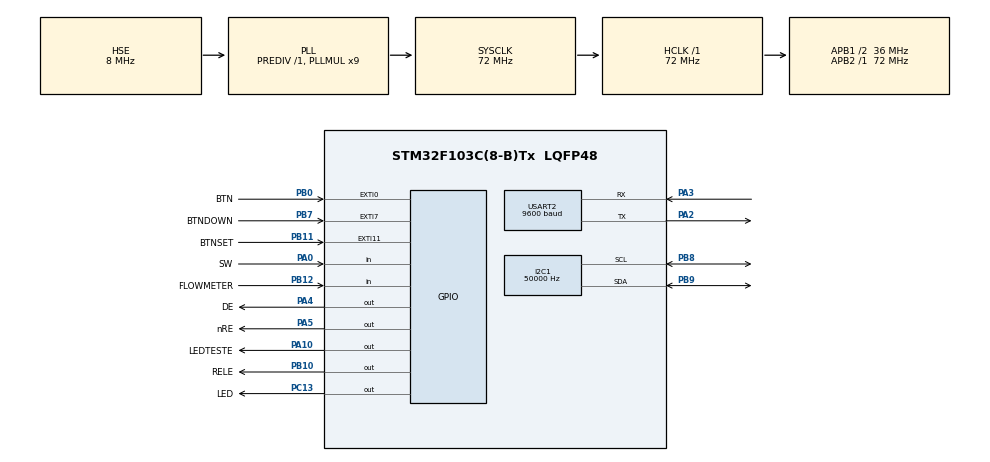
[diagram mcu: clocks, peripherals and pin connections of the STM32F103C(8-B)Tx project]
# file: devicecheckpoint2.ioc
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I2C1.ClockSpeed=50000
Mcu.Family=STM32F1
Mcu.Name=STM32F103C(8-B)Tx
Mcu.Package=LQFP48
NVIC.EXTI0_IRQn=true\:4\:0\:true\:false\:true\:true\:true
NVIC.EXTI15_10_IRQn=true\:3\:0\:true\:false\:true\:true\:true
NVIC.EXTI9_5_IRQn=true\:4\:0\:true\:false\:true\:true\:true
NVIC.PriorityGroup=NVIC_PRIORITYGROUP_4
NVIC.TIM2_IRQn=true\:2\:0\:true\:false\:true\:true\:true
NVIC.USART2_IRQn=true\:1\:0\:true\:false\:true\:true\:true
PA0-WKUP.GPIO_Label=SW
PA0-WKUP.GPIO_PuPd=GPIO_PULLUP
PA0-WKUP.Signal=GPIO_Input
PA10.GPIO_Label=LEDTESTE
PA10.Signal=GPIO_Output
PA13.Mode=Serial_Wire
PA13.Signal=SYS_JTMS-SWDIO
PA14.Mode=Serial_Wire
PA14.Signal=SYS_JTCK-SWCLK
PA2.Mode=Asynchronous
PA2.Signal=USART2_TX
PA3.Mode=Asynchronous
PA3.Signal=USART2_RX
PA4.GPIO_Label=DE
PA4.Signal=GPIO_Output
PA5.GPIO_Label=nRE
PA5.Signal=GPIO_Output
PB0.GPIO_Label=BTN
PB0.GPIO_ModeDefaultEXTI=GPIO_MODE_IT_FALLING
PB0.GPIO_PuPd=GPIO_NOPULL
PB0.Signal=GPXTI0
PB10.GPIO_Label=RELE
PB10.Signal=GPIO_Output
PB11.GPIO_Label=BTNSET
PB11.GPIO_ModeDefaultEXTI=GPIO_MODE_IT_FALLING
PB11.Signal=GPXTI11
PB12.GPIO_Label=FLOWMETER
PB12.Signal=GPIO_Input
PB7.GPIO_Label=BTNDOWN
PB7.GPIO_ModeDefaultEXTI=GPIO_MODE_IT_FALLING
PB7.Signal=GPXTI7
PB8.Mode=I2C
PB8.Signal=I2C1_SCL
PB9.Mode=I2C
PB9.Signal=I2C1_SDA
PC13-TAMPER-RTC.GPIO_Label=LED
PC13-TAMPER-RTC.Signal=GPIO_Output
PC14-OSC32_IN.Mode=LSE-External-Oscillator
PC14-OSC32_IN.Signal=RCC_OSC32_IN
PC15-OSC32_OUT.Mode=LSE-External-Oscillator
PC15-OSC32_OUT.Signal=RCC_OSC32_OUT
PD0-OSC_IN.Mode=HSE-External-Oscillator
PD0-OSC_IN.Signal=RCC_OSC_IN
PD1-OSC_OUT.Mode=HSE-External-Oscillator
PD1-OSC_OUT.Signal=RCC_OSC_OUT
ProjectManager.HeapSize=0x200
ProjectManager.StackSize=0x400
ProjectManager.TargetToolchain=TrueSTUDIO
RCC.AHBFreq_Value=72000000
RCC.APB1CLKDivider=RCC_HCLK_DIV2
RCC.APB1Freq_Value=36000000
RCC.APB1TimFreq_Value=72000000
RCC.APB2Freq_Value=72000000
RCC.APB2TimFreq_Value=72000000
RCC.HCLKFreq_Value=72000000
RCC.PLLMUL=RCC_PLL_MUL9
RCC.PLLSourceVirtual=RCC_PLLSOURCE_HSE
RCC.SYSCLKFreq_VALUE=72000000
RCC.SYSCLKSource=RCC_SYSCLKSOURCE_PLLCLK
RCC.USBFreq_Value=72000000
TIM2.Period=999
TIM2.Prescaler=71
USART2.BaudRate=9600
USART2.VirtualMode=VM_ASYNC
VP_TIM2_VS_ClockSourceINT.Mode=Internal
board=custom

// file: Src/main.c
/* USER CODE BEGIN Header */
/**
  ******************************************************************************
  * @file           : main.c
  * @brief          : Main program body
  ******************************************************************************
  * @attention
  *
  * <h2><center>&copy; Copyright (c) 2019 STMicroelectronics.
  * All rights reserved.</center></h2>
  *
  * This software component is licensed by ST under BSD 3-Clause license,
  * the "License"; You may not use this file except in compliance with the
  * License. You may obtain a copy of the License at:
  *                        opensource.org/licenses/BSD-3-Clause
  *
  ******************************************************************************
  */
/* USER CODE END Header */

#include "main.h"

/* USER CODE BEGIN Includes */
#include <stdbool.h>
#include "app.h"
#include "i2c-lcd.h"
/* USER CODE END Includes */

/* USER CODE BEGIN PTD */
static uint32_t tick_ms = 0;
/* USER CODE END PTD */

I2C_HandleTypeDef hi2c1;

TIM_HandleTypeDef htim2;

UART_HandleTypeDef huart2;

void SystemClock_Config(void);
static void MX_GPIO_Init(void);
static void MX_USART2_UART_Init(void);
static void MX_TIM2_Init(void);
static void MX_I2C1_Init(void);

int main(void)
{

  /* MCU Configuration--------------------------------------------------------*/

  /* Reset of all peripherals, Initializes the Flash interface and the Systick. */
  HAL_Init();

  /* Configure the system clock */
  SystemClock_Config();

  /* Initialize all configured peripherals */
  MX_GPIO_Init();
  MX_USART2_UART_Init();
  MX_TIM2_Init();
  MX_I2C1_Init();
  /* USER CODE BEGIN 2 */
  HAL_TIM_Base_Start_IT(&htim2);
  app_init();

  /* USER CODE END 2 */

  /* Infinite loop */
  /* USER CODE BEGIN WHILE */
  while (1)
  {

	  //HAL_GPIO_TogglePin(GPIOA, LEDTESTE_Pin);
	  //HAL_Delay(1000);
	  app_loop();
    /* USER CODE END WHILE */

  }
}

void SystemClock_Config(void)
{
  RCC_OscInitTypeDef RCC_OscInitStruct = {0};
  RCC_ClkInitTypeDef RCC_ClkInitStruct = {0};

  /** Initializes the CPU, AHB and APB busses clocks
  */
  RCC_OscInitStruct.OscillatorType = RCC_OSCILLATORTYPE_HSE;
  RCC_OscInitStruct.HSEState = RCC_HSE_ON;
  RCC_OscInitStruct.HSEPredivValue = RCC_HSE_PREDIV_DIV1;
  RCC_OscInitStruct.HSIState = RCC_HSI_ON;
  RCC_OscInitStruct.PLL.PLLState = RCC_PLL_ON;
  RCC_OscInitStruct.PLL.PLLSource = RCC_PLLSOURCE_HSE;
  RCC_OscInitStruct.PLL.PLLMUL = RCC_PLL_MUL9;
  if (HAL_RCC_OscConfig(&RCC_OscInitStruct) != HAL_OK)
  {
    Error_Handler();
  }
  /** Initializes the CPU, AHB and APB busses clocks
  */
  RCC_ClkInitStruct.ClockType = RCC_CLOCKTYPE_HCLK|RCC_CLOCKTYPE_SYSCLK
                              |RCC_CLOCKTYPE_PCLK1|RCC_CLOCKTYPE_PCLK2;
  RCC_ClkInitStruct.SYSCLKSource = RCC_SYSCLKSOURCE_PLLCLK;
  RCC_ClkInitStruct.AHBCLKDivider = RCC_SYSCLK_DIV1;
  RCC_ClkInitStruct.APB1CLKDivider = RCC_HCLK_DIV2;
  RCC_ClkInitStruct.APB2CLKDivider = RCC_HCLK_DIV1;

  if (HAL_RCC_ClockConfig(&RCC_ClkInitStruct, FLASH_LATENCY_2) != HAL_OK)
  {
    Error_Handler();
  }
}

static void MX_I2C1_Init(void)
{

  hi2c1.Instance = I2C1;
  hi2c1.Init.ClockSpeed = 50000;
  hi2c1.Init.DutyCycle = I2C_DUTYCYCLE_2;
  hi2c1.Init.OwnAddress1 = 0;
  hi2c1.Init.AddressingMode = I2C_ADDRESSINGMODE_7BIT;
  hi2c1.Init.DualAddressMode = I2C_DUALADDRESS_DISABLE;
  hi2c1.Init.OwnAddress2 = 0;
  hi2c1.Init.GeneralCallMode = I2C_GENERALCALL_DISABLE;
  hi2c1.Init.NoStretchMode = I2C_NOSTRETCH_DISABLE;
  if (HAL_I2C_Init(&hi2c1) != HAL_OK)
  {
    Error_Handler();
  }

}

static void MX_TIM2_Init(void)
{

  TIM_ClockConfigTypeDef sClockSourceConfig = {0};
  TIM_MasterConfigTypeDef sMasterConfig = {0};

  htim2.Instance = TIM2;
  htim2.Init.Prescaler = 71;
  htim2.Init.CounterMode = TIM_COUNTERMODE_UP;
  htim2.Init.Period = 999;
  htim2.Init.ClockDivision = TIM_CLOCKDIVISION_DIV1;
  htim2.Init.AutoReloadPreload = TIM_AUTORELOAD_PRELOAD_DISABLE;
  if (HAL_TIM_Base_Init(&htim2) != HAL_OK)
  {
    Error_Handler();
  }
  sClockSourceConfig.ClockSource = TIM_CLOCKSOURCE_INTERNAL;
  if (HAL_TIM_ConfigClockSource(&htim2, &sClockSourceConfig) != HAL_OK)
  {
    Error_Handler();
  }
  sMasterConfig.MasterOutputTrigger = TIM_TRGO_RESET;
  sMasterConfig.MasterSlaveMode = TIM_MASTERSLAVEMODE_DISABLE;
  if (HAL_TIMEx_MasterConfigSynchronization(&htim2, &sMasterConfig) != HAL_OK)
  {
    Error_Handler();
  }

}

static void MX_USART2_UART_Init(void)
{

  huart2.Instance = USART2;
  huart2.Init.BaudRate = 9600;
  huart2.Init.WordLength = UART_WORDLENGTH_8B;
  huart2.Init.StopBits = UART_STOPBITS_1;
  huart2.Init.Parity = UART_PARITY_NONE;
  huart2.Init.Mode = UART_MODE_TX_RX;
  huart2.Init.HwFlowCtl = UART_HWCONTROL_NONE;
  huart2.Init.OverSampling = UART_OVERSAMPLING_16;
  if (HAL_UART_Init(&huart2) != HAL_OK)
  {
    Error_Handler();
  }

}

static void MX_GPIO_Init(void)
{
  GPIO_InitTypeDef GPIO_InitStruct = {0};

  /* GPIO Ports Clock Enable */
  __HAL_RCC_GPIOC_CLK_ENABLE();
  __HAL_RCC_GPIOD_CLK_ENABLE();
  __HAL_RCC_GPIOA_CLK_ENABLE();
  __HAL_RCC_GPIOB_CLK_ENABLE();

  /*Configure GPIO pin Output Level */
  HAL_GPIO_WritePin(LED_GPIO_Port, LED_Pin, GPIO_PIN_RESET);

  /*Configure GPIO pin Output Level */
  HAL_GPIO_WritePin(GPIOA, DE_Pin|nRE_Pin|LEDTESTE_Pin, GPIO_PIN_RESET);

  /*Configure GPIO pin Output Level */
  HAL_GPIO_WritePin(RELE_GPIO_Port, RELE_Pin, GPIO_PIN_RESET);

  /*Configure GPIO pin : LED_Pin */
  GPIO_InitStruct.Pin = LED_Pin;
  GPIO_InitStruct.Mode = GPIO_MODE_OUTPUT_PP;
  GPIO_InitStruct.Pull = GPIO_NOPULL;
  GPIO_InitStruct.Speed = GPIO_SPEED_FREQ_LOW;
  HAL_GPIO_Init(LED_GPIO_Port, &GPIO_InitStruct);

  /*Configure GPIO pin : SW_Pin */
  GPIO_InitStruct.Pin = SW_Pin;
  GPIO_InitStruct.Mode = GPIO_MODE_INPUT;
  GPIO_InitStruct.Pull = GPIO_PULLUP;
  HAL_GPIO_Init(SW_GPIO_Port, &GPIO_InitStruct);

  /*Configure GPIO pins : DE_Pin nRE_Pin LEDTESTE_Pin */
  GPIO_InitStruct.Pin = DE_Pin|nRE_Pin|LEDTESTE_Pin;
  GPIO_InitStruct.Mode = GPIO_MODE_OUTPUT_PP;
  GPIO_InitStruct.Pull = GPIO_NOPULL;
  GPIO_InitStruct.Speed = GPIO_SPEED_FREQ_LOW;
  HAL_GPIO_Init(GPIOA, &GPIO_InitStruct);

  /*Configure GPIO pins : BTN_Pin BTNSET_Pin BTNDOWN_Pin */
  GPIO_InitStruct.Pin = BTN_Pin|BTNSET_Pin|BTNDOWN_Pin;
  GPIO_InitStruct.Mode = GPIO_MODE_IT_FALLING;
  GPIO_InitStruct.Pull = GPIO_NOPULL;
  HAL_GPIO_Init(GPIOB, &GPIO_InitStruct);

  /*Configure GPIO pin : RELE_Pin */
  GPIO_InitStruct.Pin = RELE_Pin;
  GPIO_InitStruct.Mode = GPIO_MODE_OUTPUT_PP;
  GPIO_InitStruct.Pull = GPIO_NOPULL;
  GPIO_InitStruct.Speed = GPIO_SPEED_FREQ_LOW;
  HAL_GPIO_Init(RELE_GPIO_Port, &GPIO_InitStruct);

  /*Configure GPIO pin : FLOWMETER_Pin */
  GPIO_InitStruct.Pin = FLOWMETER_Pin;
  GPIO_InitStruct.Mode = GPIO_MODE_INPUT;
  GPIO_InitStruct.Pull = GPIO_NOPULL;
  HAL_GPIO_Init(FLOWMETER_GPIO_Port, &GPIO_InitStruct);

  /* EXTI interrupt init*/
  HAL_NVIC_SetPriority(EXTI0_IRQn, 4, 0);
  HAL_NVIC_EnableIRQ(EXTI0_IRQn);

  HAL_NVIC_SetPriority(EXTI9_5_IRQn, 4, 0);
  HAL_NVIC_EnableIRQ(EXTI9_5_IRQn);

  HAL_NVIC_SetPriority(EXTI15_10_IRQn, 3, 0);
  HAL_NVIC_EnableIRQ(EXTI15_10_IRQn);

}

void Error_Handler(void)
{
}

/************************ (C) COPYRIGHT STMicroelectronics *****END OF FILE****/
